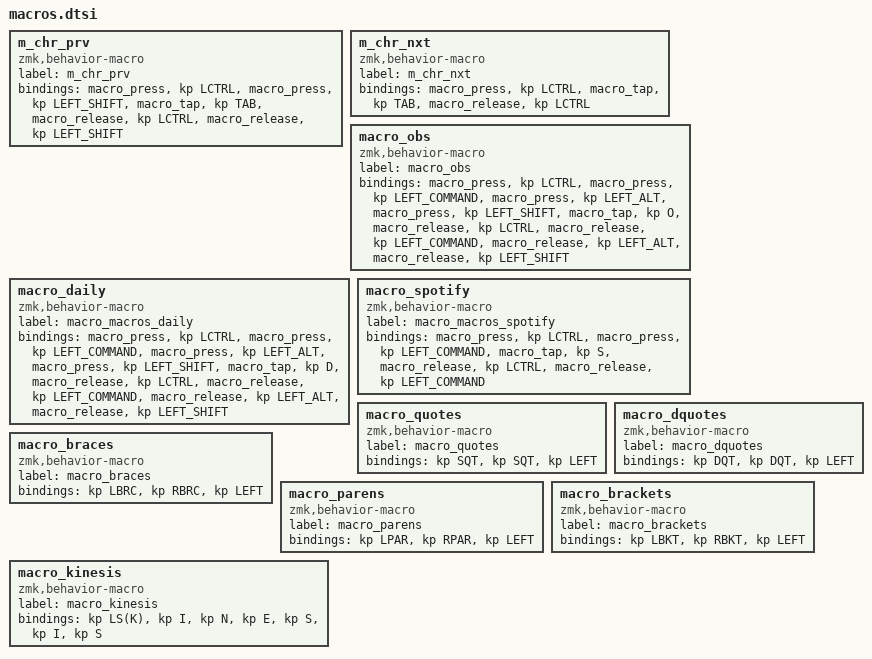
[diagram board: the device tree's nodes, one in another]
m_chr_prv: m_chr_prv {
compatible = "zmk,behavior-macro";
label = "m_chr_prv";
#binding-cells = <0>;
bindings = <&macro_press &kp LCTRL>, <&macro_press &kp LEFT_SHIFT>, <&macro_tap &kp TAB>, <&macro_release &kp LCTRL>, <&macro_release &kp LEFT_SHIFT>;
};
m_chr_nxt: m_chr_nxt {
compatible = "zmk,behavior-macro";
label = "m_chr_nxt";
#binding-cells = <0>;
bindings = <&macro_press &kp LCTRL>, <&macro_tap &kp TAB>, <&macro_release &kp LCTRL>;
};
macro_obs: macro_obs {
compatible = "zmk,behavior-macro";
label = "macro_obs";
#binding-cells = <0>;
bindings = <&macro_press &kp LCTRL>, <&macro_press &kp LEFT_COMMAND>, <&macro_press &kp LEFT_ALT>, <&macro_press &kp LEFT_SHIFT>, <&macro_tap &kp O>, <&macro_release &kp LCTRL>, <&macro_release &kp LEFT_COMMAND>, <&macro_release &kp LEFT_ALT>, <&macro_release &kp LEFT_SHIFT>;
};
macro_daily: macro_daily{
compatible = "zmk,behavior-macro";
label = "macro_macros_daily";
#binding-cells = <0>;
bindings = <&macro_press &kp LCTRL>, <&macro_press &kp LEFT_COMMAND>, <&macro_press &kp LEFT_ALT>, <&macro_press &kp LEFT_SHIFT>, <&macro_tap &kp D>, <&macro_release &kp LCTRL>, <&macro_release &kp LEFT_COMMAND>, <&macro_release &kp LEFT_ALT>, <&macro_release &kp LEFT_SHIFT>;
};
macro_spotify: macro_spotify{
compatible = "zmk,behavior-macro";
label = "macro_macros_spotify";
#binding-cells = <0>;
bindings = <&macro_press &kp LCTRL>, <&macro_press &kp LEFT_COMMAND>, <&macro_tap &kp S>, <&macro_release &kp LCTRL>, <&macro_release &kp LEFT_COMMAND>;
};
macro_quotes: macro_quotes{
compatible = "zmk,behavior-macro";
label = "macro_quotes";
#binding-cells = <0>;
bindings = <&kp SQT>, <&kp SQT>, <&kp LEFT>;
};
macro_dquotes: macro_dquotes{
compatible = "zmk,behavior-macro";
label = "macro_dquotes";
#binding-cells = <0>;
bindings = <&kp DQT>, <&kp DQT>, <&kp LEFT>;
};
macro_braces: macro_braces{
compatible = "zmk,behavior-macro";
label = "macro_braces";
#binding-cells = <0>;
bindings = <&kp LBRC>, <&kp RBRC>, <&kp LEFT>;
};
macro_parens: macro_parens{
compatible = "zmk,behavior-macro";
label = "macro_parens";
#binding-cells = <0>;
bindings = <&kp LPAR>, <&kp RPAR>, <&kp LEFT>;
};
macro_brackets: macro_brackets{
compatible = "zmk,behavior-macro";
label = "macro_brackets";
#binding-cells = <0>;
bindings = <&kp LBKT>, <&kp RBKT>, <&kp LEFT>;
};
macro_kinesis: macro_kinesis{
compatible = "zmk,behavior-macro";
label = "macro_kinesis";
#binding-cells = <0>;
bindings = <&kp LS(K)>, <&kp I>, <&kp N>, <&kp E>, <&kp S>, <&kp I>, <&kp S>;
};
